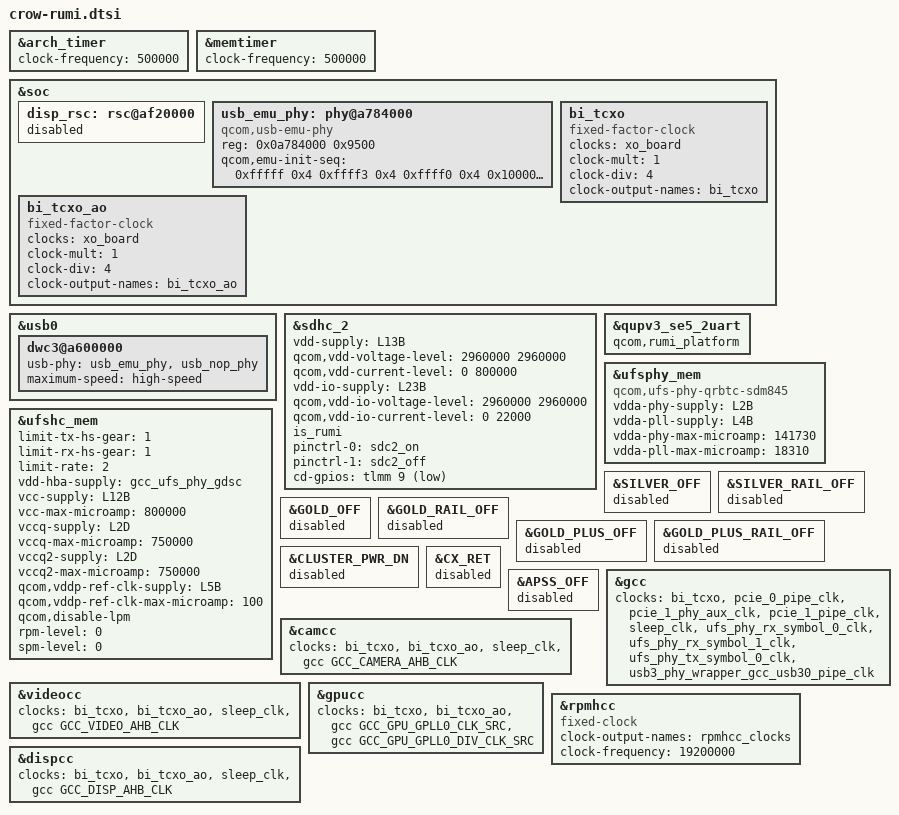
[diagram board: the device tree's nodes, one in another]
#include <dt-bindings/clock/qcom,gcc-crow.h>
#include <dt-bindings/gpio/gpio.h>

&arch_timer {
	clock-frequency = <500000>;
};

&memtimer {
	clock-frequency = <500000>;
};

&soc {
	disp_rsc: rsc@af20000 {
		status = "disabled";
	};

	usb_emu_phy: phy@a784000 {
		compatible = "qcom,usb-emu-phy";
		reg = <0x0a784000 0x9500>;

		qcom,emu-init-seq = <0xfffff 0x4
		     0xffff3 0x4
		     0xffff0 0x4
		     0x100000 0x20
		     0x0 0x20
		     0x000101F0 0x20
		     0x00100000 0x3c
		     0x0 0x3c
		     0x0010060 0x3c
		     0x0 0x4>;
	};

	bi_tcxo: bi_tcxo {
		compatible = "fixed-factor-clock";
		clocks = <&xo_board>;
		clock-mult = <1>;
		clock-div = <4>;
		#clock-cells = <0>;
		clock-output-names = "bi_tcxo";
	};

	bi_tcxo_ao: bi_tcxo_ao {
		compatible = "fixed-factor-clock";
		clocks = <&xo_board>;
		clock-mult = <1>;
		clock-div = <4>;
		#clock-cells = <0>;
		clock-output-names = "bi_tcxo_ao";
	};
};

&usb0 {
	dwc3@a600000 {
		usb-phy = <&usb_emu_phy>, <&usb_nop_phy>;
		maximum-speed = "high-speed";
	};
};

&sdhc_2 {
	status = "ok";
	vdd-supply = <&L13B>;
	qcom,vdd-voltage-level = <2960000 2960000>;
	qcom,vdd-current-level = <0 800000>;

	vdd-io-supply = <&L23B>;
	qcom,vdd-io-voltage-level = <2960000 2960000>;
	qcom,vdd-io-current-level = <0 22000>;

	is_rumi;

	pinctrl-names = "default", "sleep";
	pinctrl-0 = <&sdc2_on>;
	pinctrl-1 = <&sdc2_off>;

	cd-gpios = <&tlmm 9 GPIO_ACTIVE_LOW>;
};

&qupv3_se5_2uart {
	qcom,rumi_platform;
};

&ufsphy_mem {
	compatible = "qcom,ufs-phy-qrbtc-sdm845";

	vdda-phy-supply = <&L2B>;
	vdda-pll-supply = <&L4B>;
	vdda-phy-max-microamp = <141730>;
	vdda-pll-max-microamp = <18310>;

	status = "ok";
};

&ufshc_mem {
	limit-tx-hs-gear = <1>;
	limit-rx-hs-gear = <1>;
	limit-rate = <2>; /* HS Rate-B */

	vdd-hba-supply = <&gcc_ufs_phy_gdsc>;

	vcc-supply = <&L12B>;
	vcc-max-microamp = <800000>;

	vccq-supply = <&L2D>;
	vccq-max-microamp = <750000>;

	vccq2-supply = <&L2D>;
	vccq2-max-microamp = <750000>;

	qcom,vddp-ref-clk-supply = <&L5B>;
	qcom,vddp-ref-clk-max-microamp = <100>;

	qcom,disable-lpm;
	rpm-level = <0>;
	spm-level = <0>;

	status = "ok";
};

&SILVER_OFF {
	status = "disabled";
};

&SILVER_RAIL_OFF {
	status = "disabled";
};

&GOLD_OFF {
	status = "disabled";
};

&GOLD_RAIL_OFF {
	status = "disabled";
};

&GOLD_PLUS_OFF {
	status = "disabled";
};

&GOLD_PLUS_RAIL_OFF {
	status = "disabled";
};

&CLUSTER_PWR_DN {
	status = "disabled";
};

&CX_RET {
	status = "disabled";
};

&APSS_OFF {
	status = "disabled";
};

&gcc {
		clocks = <&bi_tcxo>,
			 <&pcie_0_pipe_clk>,
			 <&pcie_1_phy_aux_clk>,
			 <&pcie_1_pipe_clk>,
			 <&sleep_clk>,
			 <&ufs_phy_rx_symbol_0_clk>,
			 <&ufs_phy_rx_symbol_1_clk>,
			 <&ufs_phy_tx_symbol_0_clk>,
			 <&usb3_phy_wrapper_gcc_usb30_pipe_clk>;
};

&camcc {
	clocks = <&bi_tcxo>,
		 <&bi_tcxo_ao>,
		 <&sleep_clk>,
		 <&gcc GCC_CAMERA_AHB_CLK>;
};

&videocc {
	clocks = <&bi_tcxo>,
		 <&bi_tcxo_ao>,
		 <&sleep_clk>,
		 <&gcc GCC_VIDEO_AHB_CLK>;
};

&gpucc {
	clocks = <&bi_tcxo>,
		 <&bi_tcxo_ao>,
		 <&gcc GCC_GPU_GPLL0_CLK_SRC>,
		 <&gcc GCC_GPU_GPLL0_DIV_CLK_SRC>;
};

&rpmhcc {
	compatible = "fixed-clock";
	clock-output-names = "rpmhcc_clocks";
	clock-frequency = <19200000>;
};

&dispcc {
	clocks = <&bi_tcxo>,
		<&bi_tcxo_ao>,
		<&sleep_clk>,
		<&gcc GCC_DISP_AHB_CLK>;
};
